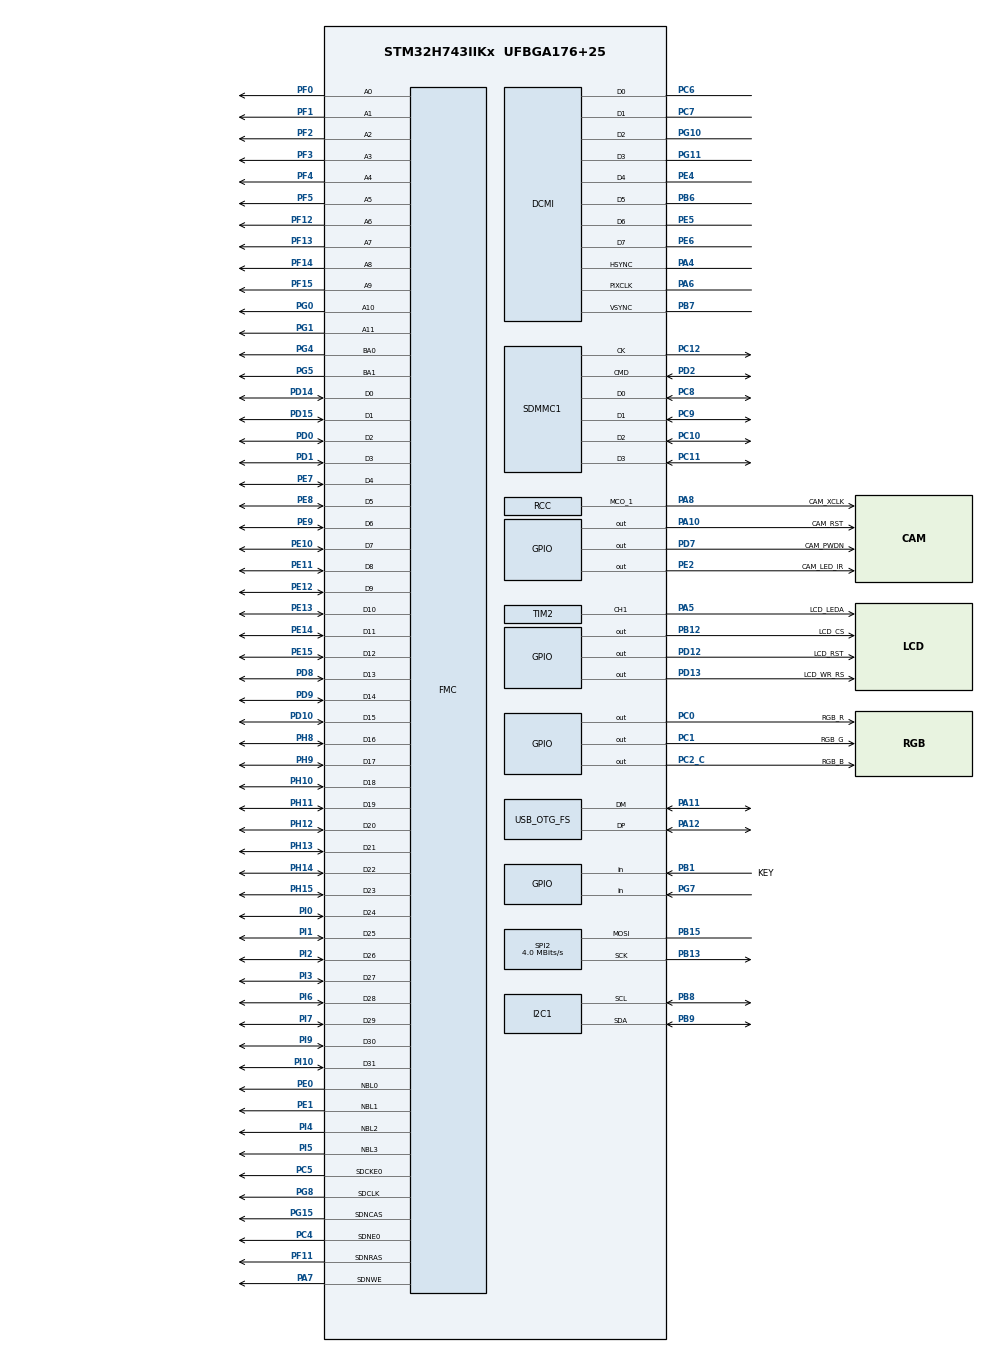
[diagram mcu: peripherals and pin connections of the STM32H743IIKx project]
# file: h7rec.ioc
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CORTEX_M7.AccessPermission_S-Cortex_Memory_Protection_Unit_Region1_Settings_S=MPU_REGION_FULL_ACCESS
CORTEX_M7.AccessPermission_Spec=MPU_REGION_NO_ACCESS
CORTEX_M7.BaseAddress_S-Cortex_Memory_Protection_Unit_Region1_Settings_S=0xC0000000
CORTEX_M7.BaseAddress_Spec=0x0
CORTEX_M7.DisableExec_S-Cortex_Memory_Protection_Unit_Region1_Settings_S=MPU_INSTRUCTION_ACCESS_DISABLE
CORTEX_M7.Enable_S-Cortex_Memory_Protection_Unit_Region1_Settings_S=MPU_REGION_ENABLE
CORTEX_M7.IsBufferable_S-Cortex_Memory_Protection_Unit_Region1_Settings_S=MPU_ACCESS_BUFFERABLE
CORTEX_M7.IsBufferable_Spec=MPU_ACCESS_NOT_BUFFERABLE
CORTEX_M7.IsCacheable_S-Cortex_Memory_Protection_Unit_Region1_Settings_S=MPU_ACCESS_CACHEABLE
CORTEX_M7.IsCacheable_Spec=MPU_ACCESS_NOT_CACHEABLE
CORTEX_M7.IsShareable_S-Cortex_Memory_Protection_Unit_Region1_Settings_S=MPU_ACCESS_SHAREABLE
CORTEX_M7.Size_S-Cortex_Memory_Protection_Unit_Region1_Settings_S=MPU_REGION_SIZE_32MB
CORTEX_M7.Size_Spec=MPU_REGION_SIZE_4GB
CORTEX_M7.SubRegionDisable_S-Cortex_Memory_Protection_Unit_Region1_Settings_S=0x0
CORTEX_M7.SubRegionDisable_Spec=0x87
CORTEX_M7.TypeExtField_S-Cortex_Memory_Protection_Unit_Region1_Settings_S=MPU_TEX_LEVEL1
CORTEX_M7.TypeExtField_Spec=MPU_TEX_LEVEL0
CORTEX_M7.default_mode_Activation=1
DCMI.PCKPolarity=DCMI_PCKPOLARITY_RISING
DCMI.VSPolarity=DCMI_VSPOLARITY_HIGH
Dma.DCMI.0.Direction=DMA_PERIPH_TO_MEMORY
Dma.DCMI.0.EventEnable=DISABLE
Dma.DCMI.0.FIFOMode=DMA_FIFOMODE_ENABLE
Dma.DCMI.0.FIFOThreshold=DMA_FIFO_THRESHOLD_FULL
Dma.DCMI.0.Instance=DMA1_Stream0
Dma.DCMI.0.MemBurst=DMA_MBURST_INC4
Dma.DCMI.0.MemDataAlignment=DMA_MDATAALIGN_WORD
Dma.DCMI.0.MemInc=DMA_MINC_ENABLE
Dma.DCMI.0.Mode=DMA_NORMAL
Dma.DCMI.0.PeriphBurst=DMA_PBURST_SINGLE
Dma.DCMI.0.PeriphDataAlignment=DMA_PDATAALIGN_WORD
Dma.DCMI.0.PeriphInc=DMA_PINC_DISABLE
Dma.DCMI.0.Polarity=HAL_DMAMUX_REQ_GEN_RISING
Dma.DCMI.0.Priority=DMA_PRIORITY_VERY_HIGH
Dma.DCMI.0.RequestNumber=1
Dma.DCMI.0.SignalID=NONE
Dma.DCMI.0.SyncEnable=DISABLE
Dma.DCMI.0.SyncPolarity=HAL_DMAMUX_SYNC_NO_EVENT
Dma.DCMI.0.SyncRequestNumber=1
Dma.DCMI.0.SyncSignalID=NONE
Dma.Request0=DCMI
FATFS.BSP.number=1
FATFS0.BSP.STBoard=false
FATFS0.BSP.api=Unknown
FATFS0.BSP.instance=PG7
FATFS0.BSP.ip=GPIO
FATFS0.BSP.mode=Input
FATFS0.BSP.name=Detect_SDIO
FATFS0.BSP.solution=PG7
FMC.CASLatency1=FMC_SDRAM_CAS_LATENCY_3
FMC.ColumnBitsNumber1=FMC_SDRAM_COLUMN_BITS_NUM_9
FMC.ExitSelfRefreshDelay1=7
FMC.LoadToActiveDelay1=2
FMC.RCDDelay1=3
FMC.RPDelay1=2
FMC.ReadBurst1=FMC_SDRAM_RBURST_ENABLE
FMC.RowCycleDelay1=7
FMC.SDClockPeriod1=FMC_SDRAM_CLOCK_PERIOD_2
FMC.SelfRefreshTime1=4
FMC.WriteRecoveryTime1=2
FREERTOS.Tasks01=defaultTask,24,2048,StartDefaultTask,Default,NULL,Dynamic,NULL,NULL
FREERTOS.configCHECK_FOR_STACK_OVERFLOW=2
FREERTOS.configMINIMAL_STACK_SIZE=1024
FREERTOS.configTOTAL_HEAP_SIZE=0x20000
FREERTOS.configUSE_MALLOC_FAILED_HOOK=1
FREERTOS.configUSE_TICK_HOOK=1
I2C1.Timing=0x307075B1
Mcu.Family=STM32H7
Mcu.Name=STM32H743IIKx
Mcu.Package=UFBGA176+25
NVIC.DCMI_IRQn=true\:5\:0\:false\:false\:true\:true\:true\:true\:true
NVIC.DMA1_Stream0_IRQn=true\:5\:0\:false\:false\:true\:true\:false\:true\:true
NVIC.OTG_FS_IRQn=true\:5\:0\:false\:false\:true\:true\:true\:true\:true
NVIC.PriorityGroup=NVIC_PRIORITYGROUP_4
NVIC.SDMMC1_IRQn=true\:5\:0\:false\:false\:true\:true\:true\:true\:true
NVIC.TIM17_IRQn=true\:15\:0\:false\:false\:true\:false\:false\:true\:true
NVIC.TimeBase=TIM17_IRQn
NVIC.TimeBaseIP=TIM17
PA10.GPIO_Label=CAM_RST
PA10.Signal=GPIO_Output
PA11.Mode=Device_Only
PA11.Signal=USB_OTG_FS_DM
PA12.Mode=Device_Only
PA12.Signal=USB_OTG_FS_DP
PA13\ (JTMS/SWDIO).Mode=Serial_Wire
PA13\ (JTMS/SWDIO).Signal=DEBUG_JTMS-SWDIO
PA14\ (JTCK/SWCLK).Mode=Serial_Wire
PA14\ (JTCK/SWCLK).Signal=DEBUG_JTCK-SWCLK
PA4.Mode=Slave_8_bits_External_Synchro
PA4.Signal=DCMI_HSYNC
PA5.GPIO_Label=LCD_LEDA
PA5.Signal=S_TIM2_CH1_ETR
PA6.Mode=Slave_8_bits_External_Synchro
PA6.Signal=DCMI_PIXCLK
PA7.Signal=FMC_SDNWE
PA8.GPIO_Label=CAM_XCLK
PA8.GPIO_Speed=GPIO_SPEED_FREQ_VERY_HIGH
PA8.Mode=Clock-out-1
PA8.Signal=RCC_MCO_1
PB1.GPIO_Label=KEY
PB1.GPIO_PuPd=GPIO_PULLDOWN
PB1.Signal=GPIO_Input
PB12.GPIO_Label=LCD_CS
PB12.GPIO_Speed=GPIO_SPEED_FREQ_VERY_HIGH
PB12.PinState=GPIO_PIN_SET
PB12.Signal=GPIO_Output
PB13.GPIO_Speed=GPIO_SPEED_FREQ_VERY_HIGH
PB13.Mode=Simplex_Bidirectional_Master
PB13.Signal=SPI2_SCK
PB15.GPIO_Speed=GPIO_SPEED_FREQ_VERY_HIGH
PB15.Mode=Simplex_Bidirectional_Master
PB15.Signal=SPI2_MOSI
PB6.Mode=Slave_8_bits_External_Synchro
PB6.Signal=DCMI_D5
PB7.Mode=Slave_8_bits_External_Synchro
PB7.Signal=DCMI_VSYNC
PB8.Mode=I2C
PB8.Signal=I2C1_SCL
PB9.Mode=I2C
PB9.Signal=I2C1_SDA
PC0.GPIO_Label=RGB_R
PC0.GPIO_Speed=GPIO_SPEED_FREQ_HIGH
PC0.PinState=GPIO_PIN_SET
PC0.Signal=GPIO_Output
PC1.GPIO_Label=RGB_G
PC1.GPIO_Speed=GPIO_SPEED_FREQ_HIGH
PC1.PinState=GPIO_PIN_SET
PC1.Signal=GPIO_Output
PC10.Mode=SD_4_bits_Wide_bus
PC10.Signal=SDMMC1_D2
PC11.Mode=SD_4_bits_Wide_bus
PC11.Signal=SDMMC1_D3
PC12.Mode=SD_4_bits_Wide_bus
PC12.Signal=SDMMC1_CK
PC14-OSC32_IN\ (OSC32_IN).Mode=LSE-External-Oscillator
PC14-OSC32_IN\ (OSC32_IN).Signal=RCC_OSC32_IN
PC15-OSC32_OUT\ (OSC32_OUT).Mode=LSE-External-Oscillator
PC15-OSC32_OUT\ (OSC32_OUT).Signal=RCC_OSC32_OUT
PC2_C.GPIO_Label=RGB_B
PC2_C.GPIO_Speed=GPIO_SPEED_FREQ_HIGH
PC2_C.PinState=GPIO_PIN_SET
PC2_C.Signal=GPIO_Output
PC4.Mode=SdramChipSelect1_1
PC4.Signal=FMC_SDNE0
PC5.Mode=SdramChipSelect1_1
PC5.Signal=FMC_SDCKE0
PC6.Mode=Slave_8_bits_External_Synchro
PC6.Signal=DCMI_D0
PC7.Mode=Slave_8_bits_External_Synchro
PC7.Signal=DCMI_D1
PC8.Mode=SD_4_bits_Wide_bus
PC8.Signal=SDMMC1_D0
PC9.Mode=SD_4_bits_Wide_bus
PC9.Signal=SDMMC1_D1
PD0.Signal=FMC_D2_DA2
PD1.Signal=FMC_D3_DA3
PD10.Signal=FMC_D15_DA15
PD12.GPIO_Label=LCD_RST
PD12.Signal=GPIO_Output
PD13.GPIO_Label=LCD_WR_RS
PD13.GPIO_Speed=GPIO_SPEED_FREQ_VERY_HIGH
PD13.PinState=GPIO_PIN_SET
PD13.Signal=GPIO_Output
PD14.Signal=FMC_D0_DA0
PD15.Signal=FMC_D1_DA1
PD2.Mode=SD_4_bits_Wide_bus
PD2.Signal=SDMMC1_CMD
PD7.GPIO_Label=CAM_PWDN
PD7.PinState=GPIO_PIN_SET
PD7.Signal=GPIO_Output
PD8.Signal=FMC_D13_DA13
PD9.Signal=FMC_D14_DA14
PE0.Signal=FMC_NBL0
PE1.Signal=FMC_NBL1
PE10.Signal=FMC_D7_DA7
PE11.Signal=FMC_D8_DA8
PE12.Signal=FMC_D9_DA9
PE13.Signal=FMC_D10_DA10
PE14.Signal=FMC_D11_DA11
PE15.Signal=FMC_D12_DA12
PE2.GPIO_Label=CAM_LED_IR
PE2.Signal=GPIO_Output
PE4.Mode=Slave_8_bits_External_Synchro
PE4.Signal=DCMI_D4
PE5.Mode=Slave_8_bits_External_Synchro
PE5.Signal=DCMI_D6
PE6.Mode=Slave_8_bits_External_Synchro
PE6.Signal=DCMI_D7
PE7.Signal=FMC_D4_DA4
PE8.Signal=FMC_D5_DA5
PE9.Signal=FMC_D6_DA6
PF0.Signal=FMC_A0
PF1.Signal=FMC_A1
PF11.Signal=FMC_SDNRAS
PF12.Signal=FMC_A6
PF13.Signal=FMC_A7
PF14.Signal=FMC_A8
PF15.Signal=FMC_A9
PF2.Signal=FMC_A2
PF3.Signal=FMC_A3
PF4.Signal=FMC_A4
PF5.Signal=FMC_A5
PG0.Signal=FMC_A10
PG1.Signal=FMC_A11
PG10.Mode=Slave_8_bits_External_Synchro
PG10.Signal=DCMI_D2
PG11.Mode=Slave_8_bits_External_Synchro
PG11.Signal=DCMI_D3
PG15.Signal=FMC_SDNCAS
PG4.Signal=FMC_A14_BA0
PG5.Signal=FMC_A15_BA1
PG7.Signal=GPIO_Input
PG8.Signal=FMC_SDCLK
PH0-OSC_IN\ (PH0).Mode=HSE-External-Oscillator
PH0-OSC_IN\ (PH0).Signal=RCC_OSC_IN
PH1-OSC_OUT\ (PH1).Mode=HSE-External-Oscillator
PH1-OSC_OUT\ (PH1).Signal=RCC_OSC_OUT
PH10.Signal=FMC_D18
PH11.Signal=FMC_D19
PH12.Signal=FMC_D20
PH13.Signal=FMC_D21
PH14.Signal=FMC_D22
PH15.Signal=FMC_D23
PH8.Signal=FMC_D16
PH9.Signal=FMC_D17
PI0.Signal=FMC_D24
PI1.Signal=FMC_D25
PI10.Signal=FMC_D31
PI2.Signal=FMC_D26
PI3.Signal=FMC_D27
PI4.Signal=FMC_NBL2
PI5.Signal=FMC_NBL3
PI6.Signal=FMC_D28
PI7.Signal=FMC_D29
PI9.Signal=FMC_D30
ProjectManager.HeapSize=0x20000
ProjectManager.StackSize=0x4000
ProjectManager.TargetToolchain=MDK-ARM V5.32
RCC.ADCFreq_Value=72000000
RCC.APB1Freq_Value=120000000
RCC.APB2Freq_Value=120000000
RCC.APB3Freq_Value=120000000
RCC.APB4Freq_Value=120000000
RCC.CortexFreq_Value=480000000
RCC.D1PPRE=RCC_APB3_DIV2
RCC.D2PPRE1=RCC_APB1_DIV2
RCC.D2PPRE2=RCC_APB2_DIV2
RCC.D3PPRE=RCC_APB4_DIV2
RCC.DIVM1=1
RCC.DIVM2=1
RCC.DIVM3=2
RCC.DIVN1=80
RCC.DIVN2=12
RCC.DIVN3=32
RCC.DIVP3=3
RCC.DIVQ1=15
RCC.DIVQ3=4
RCC.DIVR2=1
RCC.HCLKFreq_Value=240000000
RCC.HPRE=RCC_HCLK_DIV2
RCC.HSE_VALUE=12000000
RCC.PLL2FRACN=0
RCC.PLL3FRACN=0
RCC.PLLFRACN=0
RCC.PLLSourceVirtual=RCC_PLLSOURCE_HSE
RCC.RCC_MCO1Source=RCC_MCO1SOURCE_HSE
RCC.SYSCLKFreq_VALUE=480000000
RCC.SYSCLKSource=RCC_SYSCLKSOURCE_PLLCLK
RCC.USBCLockSelection=RCC_USBCLKSOURCE_PLL3
RCC.USBFreq_Value=48000000
RTC.Hours=12
RTC.Month=RTC_MONTH_JULY
SDMMC1.ClockDiv=1
SDMMC1.HardwareFlowControl=SDMMC_HARDWARE_FLOW_CONTROL_ENABLE
SH.FMC_A0.0=FMC_A0,12b-sda1
SH.FMC_A1.0=FMC_A1,12b-sda1
SH.FMC_A10.0=FMC_A10,12b-sda1
SH.FMC_A11.0=FMC_A11,12b-sda1
SH.FMC_A14_BA0.0=FMC_BA0,FourSdramBanks1
SH.FMC_A15_BA1.0=FMC_BA1,FourSdramBanks1
SH.FMC_A2.0=FMC_A2,12b-sda1
SH.FMC_A3.0=FMC_A3,12b-sda1
SH.FMC_A4.0=FMC_A4,12b-sda1
SH.FMC_A5.0=FMC_A5,12b-sda1
SH.FMC_A6.0=FMC_A6,12b-sda1
SH.FMC_A7.0=FMC_A7,12b-sda1
SH.FMC_A8.0=FMC_A8,12b-sda1
SH.FMC_A9.0=FMC_A9,12b-sda1
SH.FMC_D0_DA0.0=FMC_D0,sd-32b-d1
SH.FMC_D10_DA10.0=FMC_D10,sd-32b-d1
SH.FMC_D11_DA11.0=FMC_D11,sd-32b-d1
SH.FMC_D12_DA12.0=FMC_D12,sd-32b-d1
SH.FMC_D13_DA13.0=FMC_D13,sd-32b-d1
SH.FMC_D14_DA14.0=FMC_D14,sd-32b-d1
SH.FMC_D15_DA15.0=FMC_D15,sd-32b-d1
SH.FMC_D16.0=FMC_D16,sd-32b-d1
SH.FMC_D17.0=FMC_D17,sd-32b-d1
SH.FMC_D18.0=FMC_D18,sd-32b-d1
SH.FMC_D19.0=FMC_D19,sd-32b-d1
SH.FMC_D1_DA1.0=FMC_D1,sd-32b-d1
SH.FMC_D20.0=FMC_D20,sd-32b-d1
SH.FMC_D21.0=FMC_D21,sd-32b-d1
SH.FMC_D22.0=FMC_D22,sd-32b-d1
SH.FMC_D23.0=FMC_D23,sd-32b-d1
SH.FMC_D24.0=FMC_D24,sd-32b-d1
SH.FMC_D25.0=FMC_D25,sd-32b-d1
SH.FMC_D26.0=FMC_D26,sd-32b-d1
SH.FMC_D27.0=FMC_D27,sd-32b-d1
SH.FMC_D28.0=FMC_D28,sd-32b-d1
SH.FMC_D29.0=FMC_D29,sd-32b-d1
SH.FMC_D2_DA2.0=FMC_D2,sd-32b-d1
SH.FMC_D30.0=FMC_D30,sd-32b-d1
SH.FMC_D31.0=FMC_D31,sd-32b-d1
SH.FMC_D3_DA3.0=FMC_D3,sd-32b-d1
SH.FMC_D4_DA4.0=FMC_D4,sd-32b-d1
SH.FMC_D5_DA5.0=FMC_D5,sd-32b-d1
SH.FMC_D6_DA6.0=FMC_D6,sd-32b-d1
SH.FMC_D7_DA7.0=FMC_D7,sd-32b-d1
SH.FMC_D8_DA8.0=FMC_D8,sd-32b-d1
SH.FMC_D9_DA9.0=FMC_D9,sd-32b-d1
SH.FMC_NBL0.0=FMC_NBL0,Sd4ByteEnable1
SH.FMC_NBL1.0=FMC_NBL1,Sd4ByteEnable1
SH.FMC_NBL2.0=FMC_NBL2,Sd4ByteEnable1
SH.FMC_NBL3.0=FMC_NBL3,Sd4ByteEnable1
SH.FMC_SDCLK.0=FMC_SDCLK,12b-sda1
SH.FMC_SDNCAS.0=FMC_SDNCAS,12b-sda1
SH.FMC_SDNRAS.0=FMC_SDNRAS,12b-sda1
SH.FMC_SDNWE.0=FMC_SDNWE,12b-sda1
SH.S_TIM2_CH1_ETR.0=TIM2_CH1,PWM Generation1 CH1
SPI2.BaudRatePrescaler=SPI_BAUDRATEPRESCALER_16
SPI2.CalculateBaudRate=4.0 MBits/s
SPI2.DataSize=SPI_DATASIZE_8BIT
SPI2.Direction=SPI_DIRECTION_1LINE
SPI2.Mode=SPI_MODE_MASTER
SPI2.VirtualType=VM_MASTER
TIM2.AutoReloadPreload=TIM_AUTORELOAD_PRELOAD_DISABLE
TIM2.Channel-PWM\ Generation1\ CH1=TIM_CHANNEL_1
TIM2.OCPolarity_1=TIM_OCPOLARITY_LOW
TIM2.Period=1000-1
TIM2.Prescaler=480-1
TIM2.Pulse-PWM\ Generation1\ CH1=500
USB_OTG_FS.VirtualMode=Device_Only
VP_FATFS_VS_SDIO.Mode=SDIO
VP_FREERTOS_VS_CMSIS_V2.Mode=CMSIS_V2
VP_MEMORYMAP_VS_MEMORYMAP.Mode=CurAppReg
VP_RTC_VS_RTC_Activate.Mode=RTC_Enabled
VP_RTC_VS_RTC_Calendar.Mode=RTC_Calendar
VP_SYS_VS_tim17.Mode=TIM17
board=custom

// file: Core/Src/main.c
/* USER CODE BEGIN Header */
/**
  ******************************************************************************
  * @file           : main.c
  * @brief          : Main program body
  ******************************************************************************
  * @attention
  *
  * Copyright (c) 2026 STMicroelectronics.
  * All rights reserved.
  *
  * This software is licensed under terms that can be found in the LICENSE file
  * in the root directory of this software component.
  * If no LICENSE file comes with this software, it is provided AS-IS.
  *
  ******************************************************************************
  */
/* USER CODE END Header */
#include "main.h"
#include "cmsis_os.h"
#include "dcmi.h"
#include "dma.h"
#include "fatfs.h"
#include "i2c.h"
#include "memorymap.h"
#include "rtc.h"
#include "sdmmc.h"
#include "spi.h"
#include "tim.h"
#include "gpio.h"
#include "fmc.h"

/* USER CODE BEGIN Includes */
#include "lcd.h"
#include "SEGGER_RTT.h"
#include "cherryusb_app.h"
/* USER CODE END Includes */

void SystemClock_Config(void);
static void MPU_Config(void);
void MX_FREERTOS_Init(void);

/* USER CODE BEGIN 0 */
uint32_t Get_sdram_err = 0;
/* USER CODE END 0 */

int main(void)
{

  /* USER CODE BEGIN 1 */
  SEGGER_RTT_Init();
  uint32_t ccr = SCB->CCR;
  SEGGER_RTT_printf(0, "CCR=0x%08lx D=%d I=%d\r\n",
                    SCB->CCR,
                    !!(SCB->CCR & SCB_CCR_DC_Msk),
                    !!(SCB->CCR & SCB_CCR_IC_Msk));

  /* USER CODE END 1 */

  /* MPU Configuration--------------------------------------------------------*/
  MPU_Config();

  /* MCU Configuration--------------------------------------------------------*/

  /* Reset of all peripherals, Initializes the Flash interface and the Systick. */
  HAL_Init();

  /* USER CODE BEGIN Init */
  // SEGGER_RTT_Init();
  SEGGER_RTT_WriteString(0, "SEGGER Real-Time-Terminal Sample\r\n\r\n");
  SEGGER_RTT_WriteString(0, "###### Testing SEGGER_printf() ######\r\n");
  /* USER CODE END Init */

  /* Configure the system clock */
  SystemClock_Config();

  /* Initialize all configured peripherals */
  MX_GPIO_Init();
  MX_DMA_Init();
  MX_RTC_Init();
  MX_SPI2_Init();
  MX_TIM2_Init();
  MX_SDMMC1_SD_Init();
  MX_FATFS_Init();
  MX_FMC_Init();
  MX_DCMI_Init();
  MX_I2C1_Init();
  /* USER CODE BEGIN 2 */
	HAL_TIM_PWM_Start(&htim2,TIM_CHANNEL_1);// PWM
  Get_sdram_err = SDRAM_SmokeTest(); // quick SDRAM test
  SEGGER_RTT_printf(0, "SDRAM smoke test result: %s, code=%lu\r\n",
                    Get_sdram_err == 0 ? "OK" : "ERROR",
                    (unsigned long)Get_sdram_err);
  /* USER CODE END 2 */

  /* Init scheduler */
  osKernelInitialize();

  /* Call init function for freertos objects (in cmsis_os2.c) */
  MX_FREERTOS_Init();

  /* Start scheduler */
  osKernelStart();

  /* We should never get here as control is now taken by the scheduler */

  /* Infinite loop */
  while (1)
  {

  }
}

void SystemClock_Config(void)
{
  RCC_OscInitTypeDef RCC_OscInitStruct = {0};
  RCC_ClkInitTypeDef RCC_ClkInitStruct = {0};

  /** Supply configuration update enable
  */
  HAL_PWREx_ConfigSupply(PWR_LDO_SUPPLY);

  /** Configure the main internal regulator output voltage
  */
  __HAL_PWR_VOLTAGESCALING_CONFIG(PWR_REGULATOR_VOLTAGE_SCALE0);

  while(!__HAL_PWR_GET_FLAG(PWR_FLAG_VOSRDY)) {}

  /** Initializes the RCC Oscillators according to the specified parameters
  * in the RCC_OscInitTypeDef structure.
  */
  RCC_OscInitStruct.OscillatorType = RCC_OSCILLATORTYPE_LSI|RCC_OSCILLATORTYPE_HSE;
  RCC_OscInitStruct.HSEState = RCC_HSE_ON;
  RCC_OscInitStruct.LSIState = RCC_LSI_ON;
  RCC_OscInitStruct.PLL.PLLState = RCC_PLL_ON;
  RCC_OscInitStruct.PLL.PLLSource = RCC_PLLSOURCE_HSE;
  RCC_OscInitStruct.PLL.PLLM = 1;
  RCC_OscInitStruct.PLL.PLLN = 80;
  RCC_OscInitStruct.PLL.PLLP = 2;
  RCC_OscInitStruct.PLL.PLLQ = 15;
  RCC_OscInitStruct.PLL.PLLR = 2;
  RCC_OscInitStruct.PLL.PLLRGE = RCC_PLL1VCIRANGE_3;
  RCC_OscInitStruct.PLL.PLLVCOSEL = RCC_PLL1VCOWIDE;
  RCC_OscInitStruct.PLL.PLLFRACN = 0;
  if (HAL_RCC_OscConfig(&RCC_OscInitStruct) != HAL_OK)
  {
    Error_Handler();
  }

  /** Initializes the CPU, AHB and APB buses clocks
  */
  RCC_ClkInitStruct.ClockType = RCC_CLOCKTYPE_HCLK|RCC_CLOCKTYPE_SYSCLK
                              |RCC_CLOCKTYPE_PCLK1|RCC_CLOCKTYPE_PCLK2
                              |RCC_CLOCKTYPE_D3PCLK1|RCC_CLOCKTYPE_D1PCLK1;
  RCC_ClkInitStruct.SYSCLKSource = RCC_SYSCLKSOURCE_PLLCLK;
  RCC_ClkInitStruct.SYSCLKDivider = RCC_SYSCLK_DIV1;
  RCC_ClkInitStruct.AHBCLKDivider = RCC_HCLK_DIV2;
  RCC_ClkInitStruct.APB3CLKDivider = RCC_APB3_DIV2;
  RCC_ClkInitStruct.APB1CLKDivider = RCC_APB1_DIV2;
  RCC_ClkInitStruct.APB2CLKDivider = RCC_APB2_DIV2;
  RCC_ClkInitStruct.APB4CLKDivider = RCC_APB4_DIV2;

  if (HAL_RCC_ClockConfig(&RCC_ClkInitStruct, FLASH_LATENCY_4) != HAL_OK)
  {
    Error_Handler();
  }
  HAL_RCC_MCOConfig(RCC_MCO1, RCC_MCO1SOURCE_HSE, RCC_MCODIV_1);
}

 /* MPU Configuration */

void MPU_Config(void)
{
  MPU_Region_InitTypeDef MPU_InitStruct = {0};

  /* Disables the MPU */
  HAL_MPU_Disable();

  /** Initializes and configures the Region and the memory to be protected
  */
  MPU_InitStruct.Enable = MPU_REGION_ENABLE;
  MPU_InitStruct.Number = MPU_REGION_NUMBER0;
  MPU_InitStruct.BaseAddress = 0x0;
  MPU_InitStruct.Size = MPU_REGION_SIZE_4GB;
  MPU_InitStruct.SubRegionDisable = 0x87;
  MPU_InitStruct.TypeExtField = MPU_TEX_LEVEL0;
  MPU_InitStruct.AccessPermission = MPU_REGION_NO_ACCESS;
  MPU_InitStruct.DisableExec = MPU_INSTRUCTION_ACCESS_DISABLE;
  MPU_InitStruct.IsShareable = MPU_ACCESS_SHAREABLE;
  MPU_InitStruct.IsCacheable = MPU_ACCESS_NOT_CACHEABLE;
  MPU_InitStruct.IsBufferable = MPU_ACCESS_NOT_BUFFERABLE;

  HAL_MPU_ConfigRegion(&MPU_InitStruct);

  /** Initializes and configures the Region and the memory to be protected
  */
  MPU_InitStruct.Number = MPU_REGION_NUMBER1;
  MPU_InitStruct.BaseAddress = 0xC0000000;
  MPU_InitStruct.Size = MPU_REGION_SIZE_32MB;
  MPU_InitStruct.SubRegionDisable = 0x0;
  MPU_InitStruct.TypeExtField = MPU_TEX_LEVEL1;
  MPU_InitStruct.AccessPermission = MPU_REGION_FULL_ACCESS;
  MPU_InitStruct.IsCacheable = MPU_ACCESS_CACHEABLE;
  MPU_InitStruct.IsBufferable = MPU_ACCESS_BUFFERABLE;

  HAL_MPU_ConfigRegion(&MPU_InitStruct);
  /* Enables the MPU */
  HAL_MPU_Enable(MPU_PRIVILEGED_DEFAULT);

}

void HAL_TIM_PeriodElapsedCallback(TIM_HandleTypeDef *htim)
{
  if (htim->Instance == TIM17) {
    HAL_IncTick();
  }
}

void Error_Handler(void)
{
  /* USER CODE BEGIN Error_Handler_Debug */
  /* User can add his own implementation to report the HAL error return state */
  __disable_irq();
  Fault_PrintInfo("Error_Handler", 1U);

  if ((CoreDebug->DHCSR & CoreDebug_DHCSR_C_DEBUGEN_Msk) != 0U)
  {
    __BKPT(0);
  }

  while (1)
  {
  }
  /* USER CODE END Error_Handler_Debug */
}

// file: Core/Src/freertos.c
/* USER CODE BEGIN Header */
/**
  ******************************************************************************
  * File Name          : freertos.c
  * Description        : Code for freertos applications
  ******************************************************************************
  * @attention
  *
  * Copyright (c) 2026 STMicroelectronics.
  * All rights reserved.
  *
  * This software is licensed under terms that can be found in the LICENSE file
  * in the root directory of this software component.
  * If no LICENSE file comes with this software, it is provided AS-IS.
  *
  ******************************************************************************
  */
/* USER CODE END Header */

#include "FreeRTOS.h"
#include "task.h"
#include "main.h"
#include "cmsis_os.h"

/* USER CODE BEGIN Includes */
#include "app_runtime.h"
#include "lvgl.h"
#include "SEGGER_RTT.h"
/* USER CODE END Includes */

/* Definitions for defaultTask */
osThreadId_t defaultTaskHandle;
const osThreadAttr_t defaultTask_attributes = {
  .name = "defaultTask",
  .stack_size = 2048 * 4,
  .priority = (osPriority_t) osPriorityNormal,
};

void StartDefaultTask(void *argument);

void MX_FREERTOS_Init(void); /* (MISRA C 2004 rule 8.1) */

/* Hook prototypes */
void vApplicationTickHook(void);
void vApplicationStackOverflowHook(xTaskHandle xTask, signed char *pcTaskName);
void vApplicationMallocFailedHook(void);

/* USER CODE BEGIN 3 */
void vApplicationTickHook( void )
{
   /* This function will be called by each tick interrupt if
   configUSE_TICK_HOOK is set to 1 in FreeRTOSConfig.h. User code can be
   added here, but the tick hook is called from an interrupt context, so
   code must not attempt to block, and only the interrupt safe FreeRTOS API
   functions can be used (those that end in FromISR()). */
  lv_tick_inc(1);

}
/* USER CODE END 3 */

/* USER CODE BEGIN 4 */
void vApplicationStackOverflowHook(xTaskHandle xTask, signed char *pcTaskName)
{
   /* Run time stack overflow checking is performed if
   configCHECK_FOR_STACK_OVERFLOW is defined to 1 or 2. This hook function is
   called if a stack overflow is detected. */
  (void)xTask;

  SEGGER_RTT_printf(0, "\r\n[RTOS] stack overflow: %s\r\n",
                    (pcTaskName != NULL) ? (const char *)pcTaskName : "<unknown>");
  taskDISABLE_INTERRUPTS();
  for (;;) {
  }
}
/* USER CODE END 4 */

/* USER CODE BEGIN 5 */
void vApplicationMallocFailedHook(void)
{
   /* vApplicationMallocFailedHook() will only be called if
   configUSE_MALLOC_FAILED_HOOK is set to 1 in FreeRTOSConfig.h. It is a hook
   function that will get called if a call to pvPortMalloc() fails.
   pvPortMalloc() is called internally by the kernel whenever a task, queue,
   timer or semaphore is created. It is also called by various parts of the
   demo application. If heap_1.c or heap_2.c are used, then the size of the
   heap available to pvPortMalloc() is defined by configTOTAL_HEAP_SIZE in
   FreeRTOSConfig.h, and the xPortGetFreeHeapSize() API function can be used
   to query the size of free heap space that remains (although it does not
   provide information on how the remaining heap might be fragmented). */
  SEGGER_RTT_WriteString(0, "\r\n[RTOS] malloc failed\r\n");
  taskDISABLE_INTERRUPTS();
  for (;;) {
  }
}
/* USER CODE END 5 */

void MX_FREERTOS_Init(void) {

  /* Create the thread(s) */
  /* creation of defaultTask */
  defaultTaskHandle = osThreadNew(StartDefaultTask, NULL, &defaultTask_attributes);

  /* USER CODE BEGIN RTOS_THREADS */
  /* add threads, ... */
  AppRuntime_CreateTasks();
  /* USER CODE END RTOS_THREADS */

}

void StartDefaultTask(void *argument)
{
  /* USER CODE BEGIN StartDefaultTask */
  AppRuntime_DefaultTask(argument);
  /* USER CODE END StartDefaultTask */
}

/* USER CODE BEGIN Application */

void vAssertCalled(const char *file, uint32_t line)
{
  SEGGER_RTT_printf(0, "\r\n[RTOS] assert failed: %s:%lu\r\n",
                    (file != NULL) ? file : "<unknown>",
                    (unsigned long)line);
  taskDISABLE_INTERRUPTS();
  for (;;) {
  }
}

/* USER CODE END Application */
